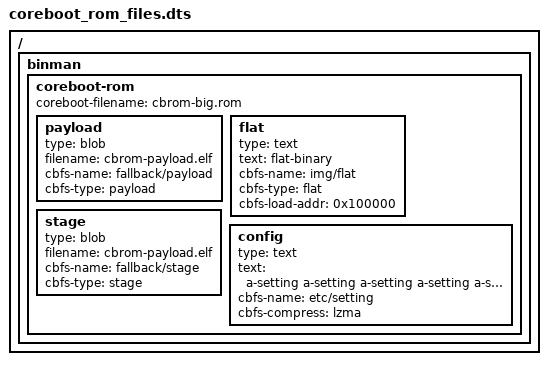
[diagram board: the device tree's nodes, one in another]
// SPDX-License-Identifier: GPL-2.0+

/dts-v1/;

/ {
	#address-cells = <1>;
	#size-cells = <1>;

	binman {
		coreboot-rom {
			coreboot-filename = "cbrom-big.rom";
			payload {
				type = "blob";
				filename = "cbrom-payload.elf";
				cbfs-name = "fallback/payload";
				cbfs-type = "payload";
			};
			flat {
				type = "text";
				text = "flat-binary";
				cbfs-name = "img/flat";
				cbfs-type = "flat";
				cbfs-load-addr = <0x100000>;
			};
			stage {
				type = "blob";
				filename = "cbrom-payload.elf";
				cbfs-name = "fallback/stage";
				cbfs-type = "stage";
			};
			config {
				type = "text";
				text = "a-setting a-setting a-setting a-setting a-setting a-setting";
				cbfs-name = "etc/setting";
				cbfs-compress = "lzma";
			};
		};
	};
};
